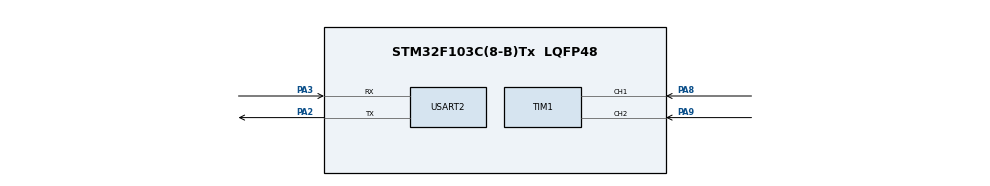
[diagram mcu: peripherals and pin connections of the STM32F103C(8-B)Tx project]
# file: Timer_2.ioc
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Mcu.Family=STM32F1
Mcu.Name=STM32F103C(8-B)Tx
Mcu.Package=LQFP48
NVIC.PriorityGroup=NVIC_PRIORITYGROUP_4
PA13.Mode=Serial_Wire
PA13.Signal=SYS_JTMS-SWDIO
PA14.Mode=Serial_Wire
PA14.Signal=SYS_JTCK-SWCLK
PA2.Mode=Asynchronous
PA2.Signal=USART2_TX
PA3.Mode=Asynchronous
PA3.Signal=USART2_RX
PA8.Signal=S_TIM1_CH1
PA9.Signal=S_TIM1_CH2
ProjectManager.HeapSize=0x200
ProjectManager.StackSize=0x400
ProjectManager.TargetToolchain=MDK-ARM V5.32
RCC.APB1Freq_Value=8000000
RCC.APB2Freq_Value=8000000
SH.S_TIM1_CH1.0=TIM1_CH1,Encoder_Interface
SH.S_TIM1_CH2.0=TIM1_CH2,Encoder_Interface
TIM1.EncoderMode=TIM_ENCODERMODE_TI12
USART2.VirtualMode=VM_ASYNC
board=custom

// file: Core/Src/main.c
/* USER CODE BEGIN Header */
/**
  ******************************************************************************
  * @file           : main.c
  * @brief          : Main program body
  ******************************************************************************
  * @attention
  *
  * Copyright (c) 2024 STMicroelectronics.
  * All rights reserved.
  *
  * This software is licensed under terms that can be found in the LICENSE file
  * in the root directory of this software component.
  * If no LICENSE file comes with this software, it is provided AS-IS.
  *
  ******************************************************************************
  */
/* USER CODE END Header */
#include "main.h"

/* USER CODE BEGIN Includes */
#define __FILE_INCOMPLETE 1
#include <stdio.h>

struct __FILE
{
  int handle;
  /* Whatever you require here. If the only file you are using is */
  /* standard output using printf() for debugging, no file handling */
  /* is required. */
};
/* FILE is typedef'd in stdio.h. */
FILE __stdout;

/* USER CODE END Includes */

TIM_HandleTypeDef htim1;

UART_HandleTypeDef huart2;

void SystemClock_Config(void);
static void MX_GPIO_Init(void);
static void MX_TIM1_Init(void);
static void MX_USART2_UART_Init(void);
/* USER CODE BEGIN PFP */
int fputc(int ch, FILE *f)
{
  HAL_UART_Transmit(&huart2, (uint8_t *) & ch, 1, 100);
  return ch;
}
int ferror(FILE *f)
{
  /* Your implementation of ferror(). */
  return 0;
}
void test(void)
{
  printf("Hello world\n");
}

/* USER CODE END PFP */

int main(void)
{

  /* MCU Configuration--------------------------------------------------------*/

  /* Reset of all peripherals, Initializes the Flash interface and the Systick. */
  HAL_Init();

  /* Configure the system clock */
  SystemClock_Config();

  /* Initialize all configured peripherals */
  MX_GPIO_Init();
  MX_TIM1_Init();
  MX_USART2_UART_Init();

  /* Infinite loop */
  while (1)
  {

  }
}

void SystemClock_Config(void)
{
  RCC_OscInitTypeDef RCC_OscInitStruct = {0};
  RCC_ClkInitTypeDef RCC_ClkInitStruct = {0};

  /** Initializes the RCC Oscillators according to the specified parameters
  * in the RCC_OscInitTypeDef structure.
  */
  RCC_OscInitStruct.OscillatorType = RCC_OSCILLATORTYPE_HSI;
  RCC_OscInitStruct.HSIState = RCC_HSI_ON;
  RCC_OscInitStruct.HSICalibrationValue = RCC_HSICALIBRATION_DEFAULT;
  RCC_OscInitStruct.PLL.PLLState = RCC_PLL_NONE;
  if (HAL_RCC_OscConfig(&RCC_OscInitStruct) != HAL_OK)
  {
    Error_Handler();
  }

  /** Initializes the CPU, AHB and APB buses clocks
  */
  RCC_ClkInitStruct.ClockType = RCC_CLOCKTYPE_HCLK|RCC_CLOCKTYPE_SYSCLK
                              |RCC_CLOCKTYPE_PCLK1|RCC_CLOCKTYPE_PCLK2;
  RCC_ClkInitStruct.SYSCLKSource = RCC_SYSCLKSOURCE_HSI;
  RCC_ClkInitStruct.AHBCLKDivider = RCC_SYSCLK_DIV1;
  RCC_ClkInitStruct.APB1CLKDivider = RCC_HCLK_DIV1;
  RCC_ClkInitStruct.APB2CLKDivider = RCC_HCLK_DIV1;

  if (HAL_RCC_ClockConfig(&RCC_ClkInitStruct, FLASH_LATENCY_0) != HAL_OK)
  {
    Error_Handler();
  }
}

static void MX_TIM1_Init(void)
{

  TIM_Encoder_InitTypeDef sConfig = {0};
  TIM_MasterConfigTypeDef sMasterConfig = {0};

  htim1.Instance = TIM1;
  htim1.Init.Prescaler = 0;
  htim1.Init.CounterMode = TIM_COUNTERMODE_UP;
  htim1.Init.Period = 65535;
  htim1.Init.ClockDivision = TIM_CLOCKDIVISION_DIV1;
  htim1.Init.RepetitionCounter = 0;
  htim1.Init.AutoReloadPreload = TIM_AUTORELOAD_PRELOAD_DISABLE;
  sConfig.EncoderMode = TIM_ENCODERMODE_TI12;
  sConfig.IC1Polarity = TIM_ICPOLARITY_RISING;
  sConfig.IC1Selection = TIM_ICSELECTION_DIRECTTI;
  sConfig.IC1Prescaler = TIM_ICPSC_DIV1;
  sConfig.IC1Filter = 0;
  sConfig.IC2Polarity = TIM_ICPOLARITY_RISING;
  sConfig.IC2Selection = TIM_ICSELECTION_DIRECTTI;
  sConfig.IC2Prescaler = TIM_ICPSC_DIV1;
  sConfig.IC2Filter = 0;
  if (HAL_TIM_Encoder_Init(&htim1, &sConfig) != HAL_OK)
  {
    Error_Handler();
  }
  sMasterConfig.MasterOutputTrigger = TIM_TRGO_RESET;
  sMasterConfig.MasterSlaveMode = TIM_MASTERSLAVEMODE_DISABLE;
  if (HAL_TIMEx_MasterConfigSynchronization(&htim1, &sMasterConfig) != HAL_OK)
  {
    Error_Handler();
  }

}

static void MX_USART2_UART_Init(void)
{

  huart2.Instance = USART2;
  huart2.Init.BaudRate = 115200;
  huart2.Init.WordLength = UART_WORDLENGTH_8B;
  huart2.Init.StopBits = UART_STOPBITS_1;
  huart2.Init.Parity = UART_PARITY_NONE;
  huart2.Init.Mode = UART_MODE_TX_RX;
  huart2.Init.HwFlowCtl = UART_HWCONTROL_NONE;
  huart2.Init.OverSampling = UART_OVERSAMPLING_16;
  if (HAL_UART_Init(&huart2) != HAL_OK)
  {
    Error_Handler();
  }

}

static void MX_GPIO_Init(void)
{

  /* GPIO Ports Clock Enable */
  __HAL_RCC_GPIOA_CLK_ENABLE();

}

void Error_Handler(void)
{
  __disable_irq();
  while (1)
  {
  }
}
